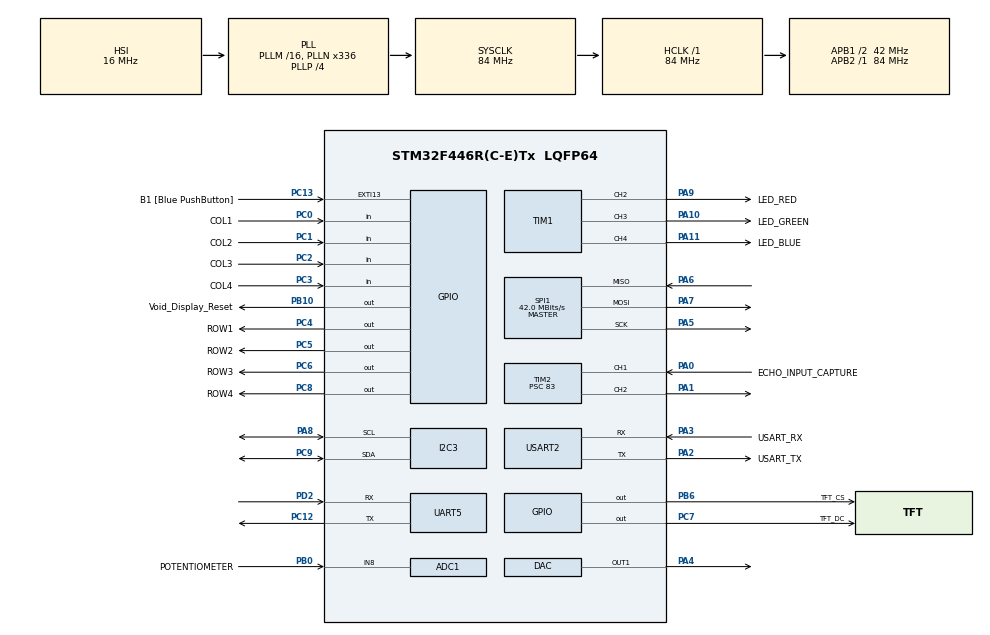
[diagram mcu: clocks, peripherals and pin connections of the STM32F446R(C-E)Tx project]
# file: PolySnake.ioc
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ADC1.Channel-0\#ChannelRegularConversion=ADC_CHANNEL_8
ADC1.NbrOfConversionFlag=1
ADC1.Rank-0\#ChannelRegularConversion=1
ADC1.SamplingTime-0\#ChannelRegularConversion=ADC_SAMPLETIME_3CYCLES
ADC1.master=1
DAC.DAC_Trigger=DAC_TRIGGER_T4_TRGO
Dma.DAC1.0.Direction=DMA_MEMORY_TO_PERIPH
Dma.DAC1.0.FIFOMode=DMA_FIFOMODE_DISABLE
Dma.DAC1.0.Instance=DMA1_Stream5
Dma.DAC1.0.MemDataAlignment=DMA_MDATAALIGN_WORD
Dma.DAC1.0.MemInc=DMA_MINC_ENABLE
Dma.DAC1.0.Mode=DMA_CIRCULAR
Dma.DAC1.0.PeriphDataAlignment=DMA_PDATAALIGN_WORD
Dma.DAC1.0.PeriphInc=DMA_PINC_DISABLE
Dma.DAC1.0.Priority=DMA_PRIORITY_HIGH
Dma.Request0=DAC1
Dma.Request1=SPI1_RX
Dma.Request2=SPI1_TX
Dma.Request3=UART5_RX
Dma.Request4=UART5_TX
Dma.SPI1_RX.1.Direction=DMA_PERIPH_TO_MEMORY
Dma.SPI1_RX.1.FIFOMode=DMA_FIFOMODE_DISABLE
Dma.SPI1_RX.1.Instance=DMA2_Stream0
Dma.SPI1_RX.1.MemDataAlignment=DMA_MDATAALIGN_BYTE
Dma.SPI1_RX.1.MemInc=DMA_MINC_ENABLE
Dma.SPI1_RX.1.Mode=DMA_NORMAL
Dma.SPI1_RX.1.PeriphDataAlignment=DMA_PDATAALIGN_BYTE
Dma.SPI1_RX.1.PeriphInc=DMA_PINC_DISABLE
Dma.SPI1_RX.1.Priority=DMA_PRIORITY_HIGH
Dma.SPI1_TX.2.Direction=DMA_MEMORY_TO_PERIPH
Dma.SPI1_TX.2.FIFOMode=DMA_FIFOMODE_DISABLE
Dma.SPI1_TX.2.Instance=DMA2_Stream3
Dma.SPI1_TX.2.MemDataAlignment=DMA_MDATAALIGN_BYTE
Dma.SPI1_TX.2.MemInc=DMA_MINC_ENABLE
Dma.SPI1_TX.2.Mode=DMA_NORMAL
Dma.SPI1_TX.2.PeriphDataAlignment=DMA_PDATAALIGN_BYTE
Dma.SPI1_TX.2.PeriphInc=DMA_PINC_DISABLE
Dma.SPI1_TX.2.Priority=DMA_PRIORITY_HIGH
Dma.UART5_RX.3.Direction=DMA_PERIPH_TO_MEMORY
Dma.UART5_RX.3.FIFOMode=DMA_FIFOMODE_DISABLE
Dma.UART5_RX.3.Instance=DMA1_Stream0
Dma.UART5_RX.3.MemDataAlignment=DMA_MDATAALIGN_BYTE
Dma.UART5_RX.3.MemInc=DMA_MINC_ENABLE
Dma.UART5_RX.3.Mode=DMA_CIRCULAR
Dma.UART5_RX.3.PeriphDataAlignment=DMA_PDATAALIGN_BYTE
Dma.UART5_RX.3.PeriphInc=DMA_PINC_DISABLE
Dma.UART5_RX.3.Priority=DMA_PRIORITY_LOW
Dma.UART5_TX.4.Direction=DMA_MEMORY_TO_PERIPH
Dma.UART5_TX.4.FIFOMode=DMA_FIFOMODE_DISABLE
Dma.UART5_TX.4.Instance=DMA1_Stream7
Dma.UART5_TX.4.MemDataAlignment=DMA_MDATAALIGN_BYTE
Dma.UART5_TX.4.MemInc=DMA_MINC_ENABLE
Dma.UART5_TX.4.Mode=DMA_NORMAL
Dma.UART5_TX.4.PeriphDataAlignment=DMA_PDATAALIGN_BYTE
Dma.UART5_TX.4.PeriphInc=DMA_PINC_DISABLE
Dma.UART5_TX.4.Priority=DMA_PRIORITY_LOW
Mcu.Family=STM32F4
Mcu.Name=STM32F446R(C-E)Tx
Mcu.Package=LQFP64
NVIC.DMA1_Stream0_IRQn=true\:0\:0\:false\:false\:true\:false\:true\:true
NVIC.DMA1_Stream5_IRQn=true\:0\:0\:false\:false\:true\:false\:true\:true
NVIC.DMA1_Stream7_IRQn=true\:0\:0\:false\:false\:true\:false\:true\:true
NVIC.DMA2_Stream0_IRQn=true\:0\:0\:false\:false\:true\:false\:true\:true
NVIC.DMA2_Stream3_IRQn=true\:0\:0\:false\:false\:true\:false\:true\:true
NVIC.I2C3_ER_IRQn=true\:0\:0\:false\:false\:true\:true\:true\:true
NVIC.I2C3_EV_IRQn=true\:0\:0\:false\:false\:true\:true\:true\:true
NVIC.PriorityGroup=NVIC_PRIORITYGROUP_0
NVIC.SPI1_IRQn=true\:0\:0\:false\:false\:true\:true\:true\:true
NVIC.TIM2_IRQn=true\:0\:0\:false\:false\:true\:true\:true\:true
NVIC.UART5_IRQn=true\:0\:0\:false\:false\:true\:true\:true\:true
NVIC.USART2_IRQn=true\:0\:0\:false\:false\:true\:true\:true\:true
PA0-WKUP.GPIO_Label=ECHO_INPUT_CAPTURE
PA0-WKUP.Signal=S_TIM2_CH1_ETR
PA1.Signal=S_TIM2_CH2
PA10.GPIO_Label=LED_GREEN
PA10.Signal=S_TIM1_CH3
PA11.GPIO_Label=LED_BLUE
PA11.Signal=S_TIM1_CH4
PA13.GPIO_Label=TMS
PA13.Mode=Serial_Wire
PA13.Signal=SYS_JTMS-SWDIO
PA14.GPIO_Label=TCK
PA14.Mode=Serial_Wire
PA14.Signal=SYS_JTCK-SWCLK
PA2.GPIO_Label=USART_TX
PA2.Mode=Asynchronous
PA2.Signal=USART2_TX
PA3.GPIO_Label=USART_RX
PA3.Mode=Asynchronous
PA3.Signal=USART2_RX
PA4.Signal=COMP_DAC1_group
PA5.Mode=Full_Duplex_Master
PA5.Signal=SPI1_SCK
PA6.Mode=Full_Duplex_Master
PA6.Signal=SPI1_MISO
PA7.Mode=Full_Duplex_Master
PA7.Signal=SPI1_MOSI
PA8.Mode=I2C
PA8.Signal=I2C3_SCL
PA9.GPIO_Label=LED_RED
PA9.Signal=S_TIM1_CH2
PB0.GPIO_Label=POTENTIOMETER
PB0.Signal=ADCx_IN8
PB10.GPIO_Label=Void_Display_Reset
PB10.Signal=GPIO_Output
PB3.GPIO_Label=SWO
PB3.Signal=SYS_JTDO-SWO
PB6.GPIO_Label=TFT_CS
PB6.Signal=GPIO_Output
PC0.GPIO_Label=COL1
PC0.GPIO_PuPd=GPIO_PULLUP
PC0.Signal=GPIO_Input
PC1.GPIO_Label=COL2
PC1.GPIO_PuPd=GPIO_PULLUP
PC1.Signal=GPIO_Input
PC12.Mode=Asynchronous
PC12.Signal=UART5_TX
PC13.GPIO_Label=B1 [Blue PushButton]
PC13.GPIO_ModeDefaultEXTI=GPIO_MODE_IT_FALLING
PC13.Signal=GPXTI13
PC14-OSC32_IN.Mode=LSE-External-Oscillator
PC14-OSC32_IN.Signal=RCC_OSC32_IN
PC15-OSC32_OUT.Mode=LSE-External-Oscillator
PC15-OSC32_OUT.Signal=RCC_OSC32_OUT
PC2.GPIO_Label=COL3
PC2.GPIO_PuPd=GPIO_PULLUP
PC2.Signal=GPIO_Input
PC3.GPIO_Label=COL4
PC3.GPIO_PuPd=GPIO_PULLUP
PC3.Signal=GPIO_Input
PC4.GPIO_Label=ROW1
PC4.GPIO_ModeDefaultOutputPP=GPIO_MODE_OUTPUT_OD
PC4.GPIO_PuPd=GPIO_NOPULL
PC4.Signal=GPIO_Output
PC5.GPIO_Label=ROW2
PC5.GPIO_ModeDefaultOutputPP=GPIO_MODE_OUTPUT_OD
PC5.GPIO_PuPd=GPIO_NOPULL
PC5.Signal=GPIO_Output
PC6.GPIO_Label=ROW3
PC6.GPIO_ModeDefaultOutputPP=GPIO_MODE_OUTPUT_OD
PC6.GPIO_PuPd=GPIO_NOPULL
PC6.Signal=GPIO_Output
PC7.GPIO_Label=TFT_DC
PC7.Signal=GPIO_Output
PC8.GPIO_Label=ROW4
PC8.GPIO_ModeDefaultOutputPP=GPIO_MODE_OUTPUT_OD
PC8.GPIO_PuPd=GPIO_NOPULL
PC8.Signal=GPIO_Output
PC9.Mode=I2C
PC9.Signal=I2C3_SDA
PD2.Mode=Asynchronous
PD2.Signal=UART5_RX
PH0-OSC_IN.Mode=HSE-External-Oscillator
PH0-OSC_IN.Signal=RCC_OSC_IN
PH1-OSC_OUT.Mode=HSE-External-Oscillator
PH1-OSC_OUT.Signal=RCC_OSC_OUT
ProjectManager.HeapSize=0x200
ProjectManager.StackSize=0x400
ProjectManager.TargetToolchain=STM32CubeIDE
RCC.48MHZClocksFreq_Value=84000000
RCC.AHBFreq_Value=84000000
RCC.APB1CLKDivider=RCC_HCLK_DIV2
RCC.APB1Freq_Value=42000000
RCC.APB1TimFreq_Value=84000000
RCC.APB2Freq_Value=84000000
RCC.APB2TimFreq_Value=84000000
RCC.CortexFreq_Value=84000000
RCC.FLatency-AdvancedSettings=FLASH_LATENCY_2
RCC.HCLKFreq_Value=84000000
RCC.HSE_VALUE=8000000
RCC.HSI_VALUE=16000000
RCC.PLLN=336
RCC.PLLP=RCC_PLLP_DIV4
RCC.SYSCLKFreq_VALUE=84000000
RCC.SYSCLKSource=RCC_SYSCLKSOURCE_PLLCLK
RCC.USBFreq_Value=168000000
RCC.VCOOutputFreq_Value=336000000
SH.ADCx_IN8.0=ADC1_IN8,IN8
SH.COMP_DAC1_group.0=DAC_OUT1,DAC_OUT1
SH.S_TIM1_CH2.0=TIM1_CH2,PWM Generation2 CH2
SH.S_TIM1_CH3.0=TIM1_CH3,PWM Generation3 CH3
SH.S_TIM1_CH4.0=TIM1_CH4,PWM Generation4 CH4
SH.S_TIM2_CH1_ETR.0=TIM2_CH1,Input_Capture1_from_TI1
SH.S_TIM2_CH2.0=TIM2_CH2,PWM Generation2 CH2
SPI1.CalculateBaudRate=42.0 MBits/s
SPI1.Direction=SPI_DIRECTION_2LINES
SPI1.Mode=SPI_MODE_MASTER
SPI1.VirtualType=VM_MASTER
TIM1.AutoReloadPreload=TIM_AUTORELOAD_PRELOAD_ENABLE
TIM1.Channel-PWM\ Generation2\ CH2=TIM_CHANNEL_2
TIM1.Channel-PWM\ Generation3\ CH3=TIM_CHANNEL_3
TIM1.Channel-PWM\ Generation4\ CH4=TIM_CHANNEL_4
TIM2.Channel-Input_Capture1_from_TI1=TIM_CHANNEL_1
TIM2.Channel-PWM\ Generation2\ CH2=TIM_CHANNEL_2
TIM2.ICPolarity_CH1=TIM_INPUTCHANNELPOLARITY_BOTHEDGE
TIM2.Period=199999
TIM2.Prescaler=83
TIM2.Pulse-PWM\ Generation2\ CH2=10
TIM2.TIM_MasterOutputTrigger=TIM_TRGO_RESET
TIM4.Period=24
TIM4.Prescaler=83
TIM4.TIM_MasterOutputTrigger=TIM_TRGO_UPDATE
UART5.VirtualMode=Asynchronous
USART2.VirtualMode=VM_ASYNC
VP_TIM1_VS_ClockSourceINT.Mode=Internal
VP_TIM2_VS_ClockSourceINT.Mode=Internal
VP_TIM4_VS_ClockSourceINT.Mode=Internal
VP_TIM6_VS_ClockSourceINT.Mode=Enable_Timer
board=NUCLEO-F446RE

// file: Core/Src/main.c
/* USER CODE BEGIN Header */
/**
  ******************************************************************************
  * @file           : main.c
  * @brief          : Main program body
  ******************************************************************************
  * @attention
  *
  * Copyright (c) 2025 STMicroelectronics.
  * All rights reserved.
  *
  * This software is licensed under terms that can be found in the LICENSE file
  * in the root directory of this software component.
  * If no LICENSE file comes with this software, it is provided AS-IS.
  *
  ******************************************************************************
  */
/* USER CODE END Header */
#include "main.h"

/* USER CODE BEGIN Includes */
#include "cpp_main.h"
/* USER CODE END Includes */

ADC_HandleTypeDef hadc1;

DAC_HandleTypeDef hdac;
DMA_HandleTypeDef hdma_dac1;

I2C_HandleTypeDef hi2c3;

SPI_HandleTypeDef hspi1;
DMA_HandleTypeDef hdma_spi1_rx;
DMA_HandleTypeDef hdma_spi1_tx;

TIM_HandleTypeDef htim1;
TIM_HandleTypeDef htim2;
TIM_HandleTypeDef htim4;
TIM_HandleTypeDef htim6;

UART_HandleTypeDef huart5;
UART_HandleTypeDef huart2;
DMA_HandleTypeDef hdma_uart5_rx;
DMA_HandleTypeDef hdma_uart5_tx;

/* USER CODE BEGIN PV */
uint8_t rxByte;
// Structure qui contient les handles pour cpp_main()
peripheral_handles handles;

/* USER CODE END PV */

void SystemClock_Config(void);
static void MX_GPIO_Init(void);
static void MX_DMA_Init(void);
static void MX_USART2_UART_Init(void);
static void MX_DAC_Init(void);
static void MX_TIM6_Init(void);
static void MX_TIM2_Init(void);
static void MX_TIM4_Init(void);
static void MX_SPI1_Init(void);
static void MX_UART5_Init(void);
static void MX_I2C3_Init(void);
static void MX_ADC1_Init(void);
static void MX_TIM1_Init(void);

int main(void)
{

  /* MCU Configuration--------------------------------------------------------*/

  /* Reset of all peripherals, Initializes the Flash interface and the Systick. */
  HAL_Init();

  /* Configure the system clock */
  SystemClock_Config();

  /* Initialize all configured peripherals */
  MX_GPIO_Init();
  MX_DMA_Init();
  MX_USART2_UART_Init();
  MX_DAC_Init();
  MX_TIM6_Init();
  MX_TIM2_Init();
  MX_TIM4_Init();
  MX_SPI1_Init();
  MX_UART5_Init();
  MX_I2C3_Init();
  MX_ADC1_Init();
  MX_TIM1_Init();
  /* USER CODE BEGIN 2 */

  HAL_UART_Receive_IT(&huart5, &rxByte, 1);

  // Remplir les handles pour le C++
  handles.hspi_tft = &hspi1;
  handles.gpio_keypad = GPIOC;
  handles.hi2c = &hi2c3;
  handles.hdac = &hdac;
  handles.htim_dac = &htim4;
  handles.htim_led = &htim1;
  handles.htim_distance = &htim2;

  cpp_main(&handles);

  /* USER CODE END 2 */

  /* Infinite loop */
  while (1)
  {

  }
}

void SystemClock_Config(void)
{
  RCC_OscInitTypeDef RCC_OscInitStruct = {0};
  RCC_ClkInitTypeDef RCC_ClkInitStruct = {0};

  /** Configure the main internal regulator output voltage
  */
  __HAL_RCC_PWR_CLK_ENABLE();
  __HAL_PWR_VOLTAGESCALING_CONFIG(PWR_REGULATOR_VOLTAGE_SCALE3);

  /** Initializes the RCC Oscillators according to the specified parameters
  * in the RCC_OscInitTypeDef structure.
  */
  RCC_OscInitStruct.OscillatorType = RCC_OSCILLATORTYPE_HSI;
  RCC_OscInitStruct.HSIState = RCC_HSI_ON;
  RCC_OscInitStruct.HSICalibrationValue = RCC_HSICALIBRATION_DEFAULT;
  RCC_OscInitStruct.PLL.PLLState = RCC_PLL_ON;
  RCC_OscInitStruct.PLL.PLLSource = RCC_PLLSOURCE_HSI;
  RCC_OscInitStruct.PLL.PLLM = 16;
  RCC_OscInitStruct.PLL.PLLN = 336;
  RCC_OscInitStruct.PLL.PLLP = RCC_PLLP_DIV4;
  RCC_OscInitStruct.PLL.PLLQ = 2;
  RCC_OscInitStruct.PLL.PLLR = 2;
  if (HAL_RCC_OscConfig(&RCC_OscInitStruct) != HAL_OK)
  {
    Error_Handler();
  }

  /** Initializes the CPU, AHB and APB buses clocks
  */
  RCC_ClkInitStruct.ClockType = RCC_CLOCKTYPE_HCLK|RCC_CLOCKTYPE_SYSCLK
                              |RCC_CLOCKTYPE_PCLK1|RCC_CLOCKTYPE_PCLK2;
  RCC_ClkInitStruct.SYSCLKSource = RCC_SYSCLKSOURCE_PLLCLK;
  RCC_ClkInitStruct.AHBCLKDivider = RCC_SYSCLK_DIV1;
  RCC_ClkInitStruct.APB1CLKDivider = RCC_HCLK_DIV2;
  RCC_ClkInitStruct.APB2CLKDivider = RCC_HCLK_DIV1;

  if (HAL_RCC_ClockConfig(&RCC_ClkInitStruct, FLASH_LATENCY_2) != HAL_OK)
  {
    Error_Handler();
  }
}

static void MX_ADC1_Init(void)
{

  ADC_ChannelConfTypeDef sConfig = {0};

  /** Configure the global features of the ADC (Clock, Resolution, Data Alignment and number of conversion)
  */
  hadc1.Instance = ADC1;
  hadc1.Init.ClockPrescaler = ADC_CLOCK_SYNC_PCLK_DIV4;
  hadc1.Init.Resolution = ADC_RESOLUTION_12B;
  hadc1.Init.ScanConvMode = DISABLE;
  hadc1.Init.ContinuousConvMode = DISABLE;
  hadc1.Init.DiscontinuousConvMode = DISABLE;
  hadc1.Init.ExternalTrigConvEdge = ADC_EXTERNALTRIGCONVEDGE_NONE;
  hadc1.Init.ExternalTrigConv = ADC_SOFTWARE_START;
  hadc1.Init.DataAlign = ADC_DATAALIGN_RIGHT;
  hadc1.Init.NbrOfConversion = 1;
  hadc1.Init.DMAContinuousRequests = DISABLE;
  hadc1.Init.EOCSelection = ADC_EOC_SINGLE_CONV;
  if (HAL_ADC_Init(&hadc1) != HAL_OK)
  {
    Error_Handler();
  }

  /** Configure for the selected ADC regular channel its corresponding rank in the sequencer and its sample time.
  */
  sConfig.Channel = ADC_CHANNEL_8;
  sConfig.Rank = 1;
  sConfig.SamplingTime = ADC_SAMPLETIME_3CYCLES;
  if (HAL_ADC_ConfigChannel(&hadc1, &sConfig) != HAL_OK)
  {
    Error_Handler();
  }

}

static void MX_DAC_Init(void)
{

  DAC_ChannelConfTypeDef sConfig = {0};

  /** DAC Initialization
  */
  hdac.Instance = DAC;
  if (HAL_DAC_Init(&hdac) != HAL_OK)
  {
    Error_Handler();
  }

  /** DAC channel OUT1 config
  */
  sConfig.DAC_Trigger = DAC_TRIGGER_T4_TRGO;
  sConfig.DAC_OutputBuffer = DAC_OUTPUTBUFFER_ENABLE;
  if (HAL_DAC_ConfigChannel(&hdac, &sConfig, DAC_CHANNEL_1) != HAL_OK)
  {
    Error_Handler();
  }

}

static void MX_I2C3_Init(void)
{

  hi2c3.Instance = I2C3;
  hi2c3.Init.ClockSpeed = 100000;
  hi2c3.Init.DutyCycle = I2C_DUTYCYCLE_2;
  hi2c3.Init.OwnAddress1 = 0;
  hi2c3.Init.AddressingMode = I2C_ADDRESSINGMODE_7BIT;
  hi2c3.Init.DualAddressMode = I2C_DUALADDRESS_DISABLE;
  hi2c3.Init.OwnAddress2 = 0;
  hi2c3.Init.GeneralCallMode = I2C_GENERALCALL_DISABLE;
  hi2c3.Init.NoStretchMode = I2C_NOSTRETCH_DISABLE;
  if (HAL_I2C_Init(&hi2c3) != HAL_OK)
  {
    Error_Handler();
  }

}

static void MX_SPI1_Init(void)
{

  /* SPI1 parameter configuration*/
  hspi1.Instance = SPI1;
  hspi1.Init.Mode = SPI_MODE_MASTER;
  hspi1.Init.Direction = SPI_DIRECTION_2LINES;
  hspi1.Init.DataSize = SPI_DATASIZE_8BIT;
  hspi1.Init.CLKPolarity = SPI_POLARITY_LOW;
  hspi1.Init.CLKPhase = SPI_PHASE_1EDGE;
  hspi1.Init.NSS = SPI_NSS_SOFT;
  hspi1.Init.BaudRatePrescaler = SPI_BAUDRATEPRESCALER_2;
  hspi1.Init.FirstBit = SPI_FIRSTBIT_MSB;
  hspi1.Init.TIMode = SPI_TIMODE_DISABLE;
  hspi1.Init.CRCCalculation = SPI_CRCCALCULATION_DISABLE;
  hspi1.Init.CRCPolynomial = 10;
  if (HAL_SPI_Init(&hspi1) != HAL_OK)
  {
    Error_Handler();
  }

}

static void MX_TIM1_Init(void)
{

  TIM_ClockConfigTypeDef sClockSourceConfig = {0};
  TIM_MasterConfigTypeDef sMasterConfig = {0};
  TIM_OC_InitTypeDef sConfigOC = {0};
  TIM_BreakDeadTimeConfigTypeDef sBreakDeadTimeConfig = {0};

  htim1.Instance = TIM1;
  htim1.Init.Prescaler = 0;
  htim1.Init.CounterMode = TIM_COUNTERMODE_UP;
  htim1.Init.Period = 65535;
  htim1.Init.ClockDivision = TIM_CLOCKDIVISION_DIV1;
  htim1.Init.RepetitionCounter = 0;
  htim1.Init.AutoReloadPreload = TIM_AUTORELOAD_PRELOAD_ENABLE;
  if (HAL_TIM_Base_Init(&htim1) != HAL_OK)
  {
    Error_Handler();
  }
  sClockSourceConfig.ClockSource = TIM_CLOCKSOURCE_INTERNAL;
  if (HAL_TIM_ConfigClockSource(&htim1, &sClockSourceConfig) != HAL_OK)
  {
    Error_Handler();
  }
  if (HAL_TIM_PWM_Init(&htim1) != HAL_OK)
  {
    Error_Handler();
  }
  sMasterConfig.MasterOutputTrigger = TIM_TRGO_RESET;
  sMasterConfig.MasterSlaveMode = TIM_MASTERSLAVEMODE_DISABLE;
  if (HAL_TIMEx_MasterConfigSynchronization(&htim1, &sMasterConfig) != HAL_OK)
  {
    Error_Handler();
  }
  sConfigOC.OCMode = TIM_OCMODE_PWM1;
  sConfigOC.Pulse = 0;
  sConfigOC.OCPolarity = TIM_OCPOLARITY_HIGH;
  sConfigOC.OCNPolarity = TIM_OCNPOLARITY_HIGH;
  sConfigOC.OCFastMode = TIM_OCFAST_DISABLE;
  sConfigOC.OCIdleState = TIM_OCIDLESTATE_RESET;
  sConfigOC.OCNIdleState = TIM_OCNIDLESTATE_RESET;
  if (HAL_TIM_PWM_ConfigChannel(&htim1, &sConfigOC, TIM_CHANNEL_2) != HAL_OK)
  {
    Error_Handler();
  }
  if (HAL_TIM_PWM_ConfigChannel(&htim1, &sConfigOC, TIM_CHANNEL_3) != HAL_OK)
  {
    Error_Handler();
  }
  sBreakDeadTimeConfig.OffStateRunMode = TIM_OSSR_DISABLE;
  sBreakDeadTimeConfig.OffStateIDLEMode = TIM_OSSI_DISABLE;
  sBreakDeadTimeConfig.LockLevel = TIM_LOCKLEVEL_OFF;
  sBreakDeadTimeConfig.DeadTime = 0;
  sBreakDeadTimeConfig.BreakState = TIM_BREAK_DISABLE;
  sBreakDeadTimeConfig.BreakPolarity = TIM_BREAKPOLARITY_HIGH;
  sBreakDeadTimeConfig.AutomaticOutput = TIM_AUTOMATICOUTPUT_DISABLE;
  if (HAL_TIMEx_ConfigBreakDeadTime(&htim1, &sBreakDeadTimeConfig) != HAL_OK)
  {
    Error_Handler();
  }
  HAL_TIM_MspPostInit(&htim1);

}

static void MX_TIM2_Init(void)
{

  TIM_ClockConfigTypeDef sClockSourceConfig = {0};
  TIM_MasterConfigTypeDef sMasterConfig = {0};
  TIM_IC_InitTypeDef sConfigIC = {0};

  htim2.Instance = TIM2;
  htim2.Init.Prescaler = 83;
  htim2.Init.CounterMode = TIM_COUNTERMODE_UP;
  htim2.Init.Period = 199999;
  htim2.Init.ClockDivision = TIM_CLOCKDIVISION_DIV1;
  htim2.Init.AutoReloadPreload = TIM_AUTORELOAD_PRELOAD_DISABLE;
  if (HAL_TIM_Base_Init(&htim2) != HAL_OK)
  {
    Error_Handler();
  }
  sClockSourceConfig.ClockSource = TIM_CLOCKSOURCE_INTERNAL;
  if (HAL_TIM_ConfigClockSource(&htim2, &sClockSourceConfig) != HAL_OK)
  {
    Error_Handler();
  }
  if (HAL_TIM_IC_Init(&htim2) != HAL_OK)
  {
    Error_Handler();
  }
  sMasterConfig.MasterOutputTrigger = TIM_TRGO_RESET;
  sMasterConfig.MasterSlaveMode = TIM_MASTERSLAVEMODE_DISABLE;
  if (HAL_TIMEx_MasterConfigSynchronization(&htim2, &sMasterConfig) != HAL_OK)
  {
    Error_Handler();
  }
  sConfigIC.ICPolarity = TIM_INPUTCHANNELPOLARITY_BOTHEDGE;
  sConfigIC.ICSelection = TIM_ICSELECTION_DIRECTTI;
  sConfigIC.ICPrescaler = TIM_ICPSC_DIV1;
  sConfigIC.ICFilter = 0;
  if (HAL_TIM_IC_ConfigChannel(&htim2, &sConfigIC, TIM_CHANNEL_1) != HAL_OK)
  {
    Error_Handler();
  }

}

static void MX_TIM4_Init(void)
{

  TIM_ClockConfigTypeDef sClockSourceConfig = {0};
  TIM_MasterConfigTypeDef sMasterConfig = {0};

  htim4.Instance = TIM4;
  htim4.Init.Prescaler = 83;
  htim4.Init.CounterMode = TIM_COUNTERMODE_UP;
  htim4.Init.Period = 24;
  htim4.Init.ClockDivision = TIM_CLOCKDIVISION_DIV1;
  htim4.Init.AutoReloadPreload = TIM_AUTORELOAD_PRELOAD_DISABLE;
  if (HAL_TIM_Base_Init(&htim4) != HAL_OK)
  {
    Error_Handler();
  }
  sClockSourceConfig.ClockSource = TIM_CLOCKSOURCE_INTERNAL;
  if (HAL_TIM_ConfigClockSource(&htim4, &sClockSourceConfig) != HAL_OK)
  {
    Error_Handler();
  }
  sMasterConfig.MasterOutputTrigger = TIM_TRGO_UPDATE;
  sMasterConfig.MasterSlaveMode = TIM_MASTERSLAVEMODE_DISABLE;
  if (HAL_TIMEx_MasterConfigSynchronization(&htim4, &sMasterConfig) != HAL_OK)
  {
    Error_Handler();
  }

}

static void MX_TIM6_Init(void)
{

  TIM_MasterConfigTypeDef sMasterConfig = {0};

  htim6.Instance = TIM6;
  htim6.Init.Prescaler = 0;
  htim6.Init.CounterMode = TIM_COUNTERMODE_UP;
  htim6.Init.Period = 65535;
  htim6.Init.AutoReloadPreload = TIM_AUTORELOAD_PRELOAD_DISABLE;
  if (HAL_TIM_Base_Init(&htim6) != HAL_OK)
  {
    Error_Handler();
  }
  sMasterConfig.MasterOutputTrigger = TIM_TRGO_RESET;
  sMasterConfig.MasterSlaveMode = TIM_MASTERSLAVEMODE_DISABLE;
  if (HAL_TIMEx_MasterConfigSynchronization(&htim6, &sMasterConfig) != HAL_OK)
  {
    Error_Handler();
  }

}

static void MX_UART5_Init(void)
{

  huart5.Instance = UART5;
  huart5.Init.BaudRate = 115200;
  huart5.Init.WordLength = UART_WORDLENGTH_8B;
  huart5.Init.StopBits = UART_STOPBITS_1;
  huart5.Init.Parity = UART_PARITY_NONE;
  huart5.Init.Mode = UART_MODE_TX_RX;
  huart5.Init.HwFlowCtl = UART_HWCONTROL_NONE;
  huart5.Init.OverSampling = UART_OVERSAMPLING_16;
  if (HAL_UART_Init(&huart5) != HAL_OK)
  {
    Error_Handler();
  }

}

static void MX_USART2_UART_Init(void)
{

  huart2.Instance = USART2;
  huart2.Init.BaudRate = 115200;
  huart2.Init.WordLength = UART_WORDLENGTH_8B;
  huart2.Init.StopBits = UART_STOPBITS_1;
  huart2.Init.Parity = UART_PARITY_NONE;
  huart2.Init.Mode = UART_MODE_TX_RX;
  huart2.Init.HwFlowCtl = UART_HWCONTROL_NONE;
  huart2.Init.OverSampling = UART_OVERSAMPLING_16;
  if (HAL_UART_Init(&huart2) != HAL_OK)
  {
    Error_Handler();
  }

}

static void MX_DMA_Init(void)
{

  /* DMA controller clock enable */
  __HAL_RCC_DMA1_CLK_ENABLE();
  __HAL_RCC_DMA2_CLK_ENABLE();

  /* DMA interrupt init */
  /* DMA1_Stream0_IRQn interrupt configuration */
  HAL_NVIC_SetPriority(DMA1_Stream0_IRQn, 0, 0);
  HAL_NVIC_EnableIRQ(DMA1_Stream0_IRQn);
  /* DMA1_Stream5_IRQn interrupt configuration */
  HAL_NVIC_SetPriority(DMA1_Stream5_IRQn, 0, 0);
  HAL_NVIC_EnableIRQ(DMA1_Stream5_IRQn);
  /* DMA1_Stream7_IRQn interrupt configuration */
  HAL_NVIC_SetPriority(DMA1_Stream7_IRQn, 0, 0);
  HAL_NVIC_EnableIRQ(DMA1_Stream7_IRQn);
  /* DMA2_Stream0_IRQn interrupt configuration */
  HAL_NVIC_SetPriority(DMA2_Stream0_IRQn, 0, 0);
  HAL_NVIC_EnableIRQ(DMA2_Stream0_IRQn);
  /* DMA2_Stream3_IRQn interrupt configuration */
  HAL_NVIC_SetPriority(DMA2_Stream3_IRQn, 0, 0);
  HAL_NVIC_EnableIRQ(DMA2_Stream3_IRQn);

}

static void MX_GPIO_Init(void)
{
  GPIO_InitTypeDef GPIO_InitStruct = {0};

  /* GPIO Ports Clock Enable */
  __HAL_RCC_GPIOC_CLK_ENABLE();
  __HAL_RCC_GPIOH_CLK_ENABLE();
  __HAL_RCC_GPIOA_CLK_ENABLE();
  __HAL_RCC_GPIOB_CLK_ENABLE();
  __HAL_RCC_GPIOD_CLK_ENABLE();

  /*Configure GPIO pin Output Level */
  HAL_GPIO_WritePin(GPIOA, ULTRASONIC_TRIG_Pin|GPIO_PIN_11, GPIO_PIN_RESET);

  /*Configure GPIO pin Output Level */
  HAL_GPIO_WritePin(GPIOC, ROW1_Pin|ROW2_Pin|ROW3_Pin|TFT_DC_Pin
                          |ROW4_Pin, GPIO_PIN_RESET);

  /*Configure GPIO pin Output Level */
  HAL_GPIO_WritePin(GPIOB, Void_Display_Reset_Pin|TFT_CS_Pin, GPIO_PIN_RESET);

  /*Configure GPIO pin : B1_Pin */
  GPIO_InitStruct.Pin = B1_Pin;
  GPIO_InitStruct.Mode = GPIO_MODE_IT_FALLING;
  GPIO_InitStruct.Pull = GPIO_NOPULL;
  HAL_GPIO_Init(B1_GPIO_Port, &GPIO_InitStruct);

  /*Configure GPIO pins : COL1_Pin COL2_Pin COL3_Pin COL4_Pin */
  GPIO_InitStruct.Pin = COL1_Pin|COL2_Pin|COL3_Pin|COL4_Pin;
  GPIO_InitStruct.Mode = GPIO_MODE_INPUT;
  GPIO_InitStruct.Pull = GPIO_PULLUP;
  HAL_GPIO_Init(GPIOC, &GPIO_InitStruct);

  /*Configure GPIO pins : ULTRASONIC_TRIG_Pin PA11 */
  GPIO_InitStruct.Pin = ULTRASONIC_TRIG_Pin|GPIO_PIN_11;
  GPIO_InitStruct.Mode = GPIO_MODE_OUTPUT_PP;
  GPIO_InitStruct.Pull = GPIO_NOPULL;
  GPIO_InitStruct.Speed = GPIO_SPEED_FREQ_LOW;
  HAL_GPIO_Init(GPIOA, &GPIO_InitStruct);

  /*Configure GPIO pins : ROW1_Pin ROW2_Pin ROW3_Pin ROW4_Pin */
  GPIO_InitStruct.Pin = ROW1_Pin|ROW2_Pin|ROW3_Pin|ROW4_Pin;
  GPIO_InitStruct.Mode = GPIO_MODE_OUTPUT_OD;
  GPIO_InitStruct.Pull = GPIO_NOPULL;
  GPIO_InitStruct.Speed = GPIO_SPEED_FREQ_LOW;
  HAL_GPIO_Init(GPIOC, &GPIO_InitStruct);

  /*Configure GPIO pins : Void_Display_Reset_Pin TFT_CS_Pin */
  GPIO_InitStruct.Pin = Void_Display_Reset_Pin|TFT_CS_Pin;
  GPIO_InitStruct.Mode = GPIO_MODE_OUTPUT_PP;
  GPIO_InitStruct.Pull = GPIO_NOPULL;
  GPIO_InitStruct.Speed = GPIO_SPEED_FREQ_LOW;
  HAL_GPIO_Init(GPIOB, &GPIO_InitStruct);

  /*Configure GPIO pin : TFT_DC_Pin */
  GPIO_InitStruct.Pin = TFT_DC_Pin;
  GPIO_InitStruct.Mode = GPIO_MODE_OUTPUT_PP;
  GPIO_InitStruct.Pull = GPIO_NOPULL;
  GPIO_InitStruct.Speed = GPIO_SPEED_FREQ_LOW;
  HAL_GPIO_Init(TFT_DC_GPIO_Port, &GPIO_InitStruct);

}

/* USER CODE BEGIN 4 */
/** @brief Systick callback.
  */

// Prevent warning: _getentropy is not implemented
int getentropy(void *buffer, size_t length)
{
  return -1;
}

/* Enable redirection of printf to UART */
#ifdef __GNUC__
#define PUTCHAR_PROTOTYPE int __io_putchar(int ch)
#else
#define PUTCHAR_PROTOTYPE int fputc(int ch, FILE *f)
#endif

PUTCHAR_PROTOTYPE
{
HAL_UART_Transmit(&huart2, (uint8_t *)&ch, 1, HAL_MAX_DELAY);
return ch;
}
/* USER CODE END 4 */

void Error_Handler(void)
{
  __disable_irq();
  while (1)
  {
  }
}
